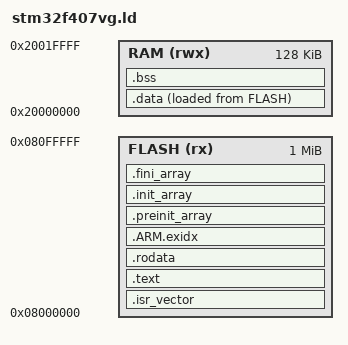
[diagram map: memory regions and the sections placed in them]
ENTRY(Reset_Handler)

MEMORY
{
    FLASH (rx)  : ORIGIN = 0x08000000, LENGTH = 1024K
    RAM   (rwx) : ORIGIN = 0x20000000, LENGTH = 128K  /* SRAM1 + SRAM2 are contiguous */
}

_estack = ORIGIN(RAM) + LENGTH(RAM);
_min_stack_size = 2K;

/* No heap and no `end` symbol: anything that pulls in malloc fails to link. */

SECTIONS
{
    .isr_vector :
    {
        . = ALIGN(4);
        KEEP(*(.isr_vector))
    } > FLASH

    .text :
    {
        *(.text*)
        KEEP(*(.init))
        KEEP(*(.fini))
    } > FLASH

    .rodata :
    {
        *(.rodata*)
    } > FLASH

    .ARM.exidx :
    {
        *(.ARM.exidx* .gnu.linkonce.armexidx.*)
    } > FLASH

    .preinit_array :
    {
        PROVIDE_HIDDEN(__preinit_array_start = .);
        KEEP(*(.preinit_array*))
        PROVIDE_HIDDEN(__preinit_array_end = .);
    } > FLASH

    .init_array :
    {
        PROVIDE_HIDDEN(__init_array_start = .);
        KEEP(*(SORT(.init_array.*)))
        KEEP(*(.init_array*))
        PROVIDE_HIDDEN(__init_array_end = .);
    } > FLASH

    .fini_array :
    {
        PROVIDE_HIDDEN(__fini_array_start = .);
        KEEP(*(SORT(.fini_array.*)))
        KEEP(*(.fini_array*))
        PROVIDE_HIDDEN(__fini_array_end = .);
    } > FLASH

    _sidata = LOADADDR(.data);

    .data :
    {
        . = ALIGN(4);
        _sdata = .;
        *(.data*)
        . = ALIGN(4);
        _edata = .;
    } > RAM AT > FLASH

    .bss :
    {
        . = ALIGN(4);
        _sbss = .;
        *(.bss*)
        *(COMMON)
        . = ALIGN(4);
        _ebss = .;
    } > RAM

    ASSERT(_ebss + _min_stack_size <= _estack, "Not enough RAM left for the stack")
}
